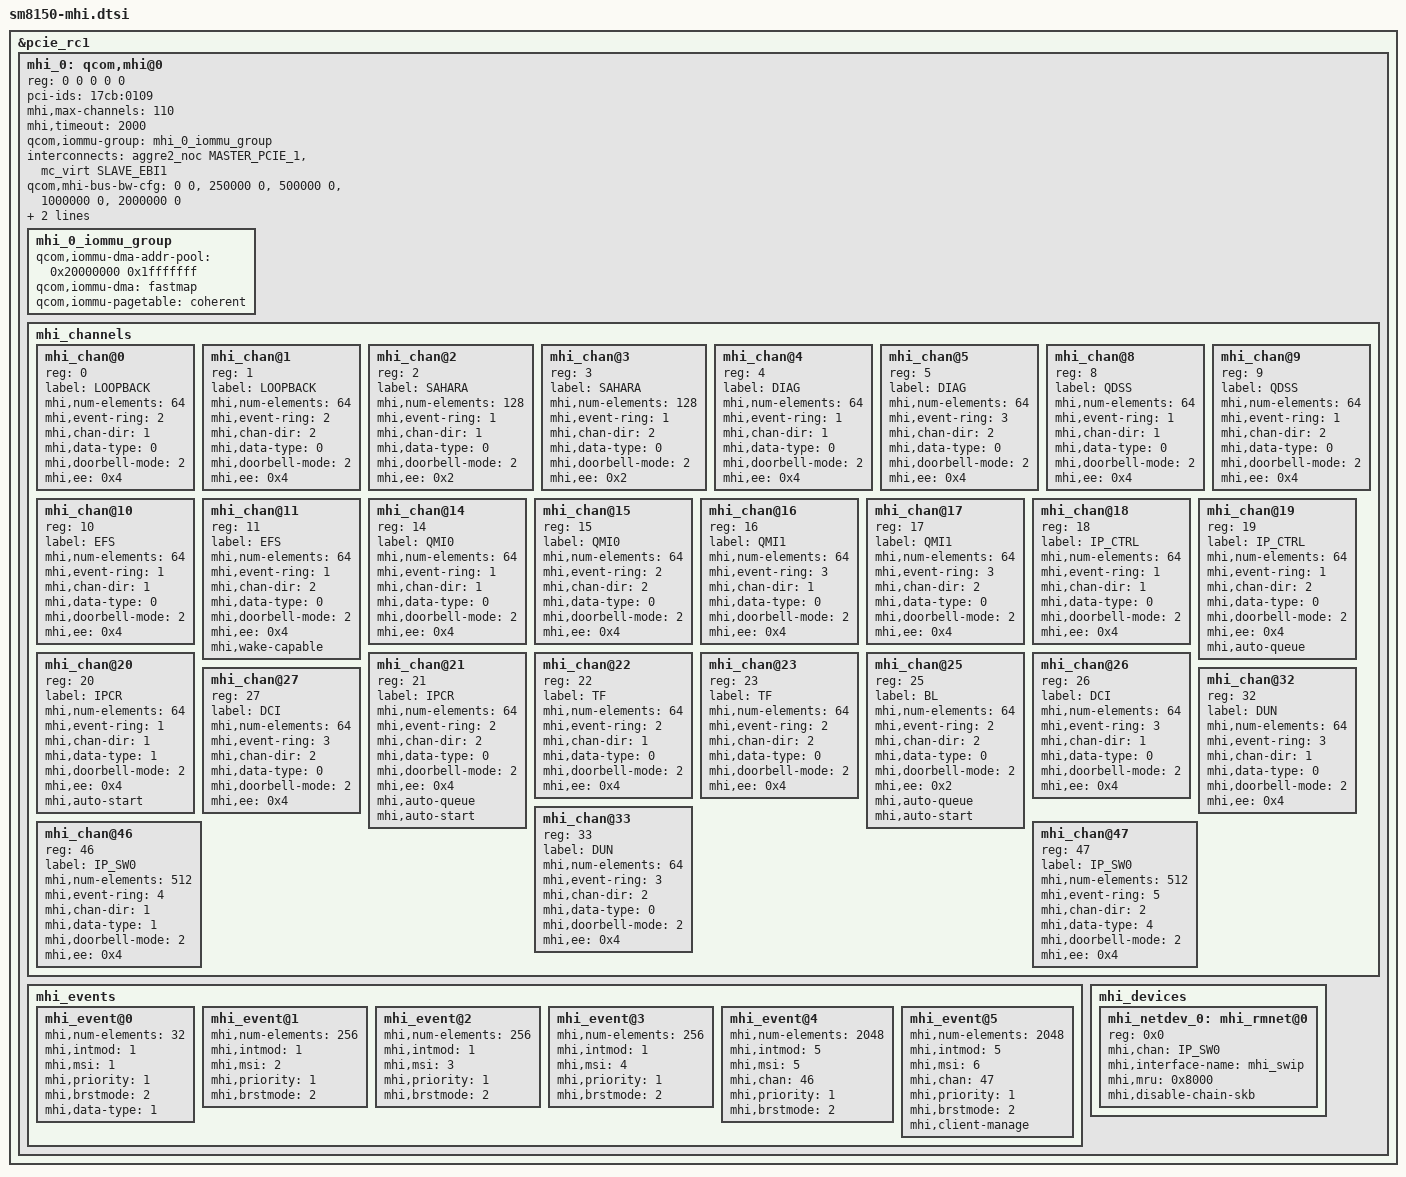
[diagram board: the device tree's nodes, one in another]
&pcie_rc1 {
	#address-cells = <5>;
	#size-cells = <0>;

	mhi_0: qcom,mhi@0 {
		reg = <0 0 0 0 0 >;

		pci-ids = "17cb:0109";

		/* mhi bus specific settings */
		mhi,max-channels = <110>;
		mhi,timeout = <2000>;
		qcom,iommu-group = <&mhi_0_iommu_group>;

		interconnect-names = "icc_path";
		interconnects = <&aggre2_noc MASTER_PCIE_1 &mc_virt SLAVE_EBI1>;
		qcom,mhi-bus-bw-cfg =
				<0 0>, /* no vote */
				<250000 0>, /* avg bw / AB: 2 GBps, peak bw / IB: no vote */
				<500000 0>, /* avg bw / AB: 4 GBps, peak bw / IB: no vote */
				<1000000 0>, /* avg bw / AB: 8 GBps, peak bw / IB: no vote */
				<2000000 0>; /* avg bw / AB: 16 GBps, peak bw / IB: no vote */
		mhi,skip-forced-suspend;
		mhi,allow-m1;

		#address-cells = <1>;
		#size-cells = <1>;

		mhi_0_iommu_group: mhi_0_iommu_group {
			qcom,iommu-dma-addr-pool = <0x20000000 0x1fffffff>;
			qcom,iommu-dma = "fastmap";
			qcom,iommu-pagetable = "coherent";
		};

		mhi_channels {
			#address-cells = <1>;
			#size-cells = <0>;
			mhi_chan@0 {
				reg = <0>;
				label = "LOOPBACK";
				mhi,num-elements = <64>;
				mhi,event-ring = <2>;
				mhi,chan-dir = <1>;
				mhi,data-type = <0>;
				mhi,doorbell-mode = <2>;
				mhi,ee = <0x4>;
			};

			mhi_chan@1 {
				reg = <1>;
				label = "LOOPBACK";
				mhi,num-elements = <64>;
				mhi,event-ring = <2>;
				mhi,chan-dir = <2>;
				mhi,data-type = <0>;
				mhi,doorbell-mode = <2>;
				mhi,ee = <0x4>;
			};

			mhi_chan@2 {
				reg = <2>;
				label = "SAHARA";
				mhi,num-elements = <128>;
				mhi,event-ring = <1>;
				mhi,chan-dir = <1>;
				mhi,data-type = <0>;
				mhi,doorbell-mode = <2>;
				mhi,ee = <0x2>;
			};

			mhi_chan@3 {
				reg = <3>;
				label = "SAHARA";
				mhi,num-elements = <128>;
				mhi,event-ring = <1>;
				mhi,chan-dir = <2>;
				mhi,data-type = <0>;
				mhi,doorbell-mode = <2>;
				mhi,ee = <0x2>;
			};

			mhi_chan@4 {
				reg = <4>;
				label = "DIAG";
				mhi,num-elements = <64>;
				mhi,event-ring = <1>;
				mhi,chan-dir = <1>;
				mhi,data-type = <0>;
				mhi,doorbell-mode = <2>;
				mhi,ee = <0x4>;
			};

			mhi_chan@5 {
				reg = <5>;
				label = "DIAG";
				mhi,num-elements = <64>;
				mhi,event-ring = <3>;
				mhi,chan-dir = <2>;
				mhi,data-type = <0>;
				mhi,doorbell-mode = <2>;
				mhi,ee = <0x4>;
			};

			mhi_chan@8 {
				reg = <8>;
				label = "QDSS";
				mhi,num-elements = <64>;
				mhi,event-ring = <1>;
				mhi,chan-dir = <1>;
				mhi,data-type = <0>;
				mhi,doorbell-mode = <2>;
				mhi,ee = <0x4>;
			};

			mhi_chan@9 {
				reg = <9>;
				label = "QDSS";
				mhi,num-elements = <64>;
				mhi,event-ring = <1>;
				mhi,chan-dir = <2>;
				mhi,data-type = <0>;
				mhi,doorbell-mode = <2>;
				mhi,ee = <0x4>;
			};

			mhi_chan@10 {
				reg = <10>;
				label = "EFS";
				mhi,num-elements = <64>;
				mhi,event-ring = <1>;
				mhi,chan-dir = <1>;
				mhi,data-type = <0>;
				mhi,doorbell-mode = <2>;
				mhi,ee = <0x4>;
			};

			mhi_chan@11 {
				reg = <11>;
				label = "EFS";
				mhi,num-elements = <64>;
				mhi,event-ring = <1>;
				mhi,chan-dir = <2>;
				mhi,data-type = <0>;
				mhi,doorbell-mode = <2>;
				mhi,ee = <0x4>;
				mhi,wake-capable;
			};

			mhi_chan@14 {
				reg = <14>;
				label = "QMI0";
				mhi,num-elements = <64>;
				mhi,event-ring = <1>;
				mhi,chan-dir = <1>;
				mhi,data-type = <0>;
				mhi,doorbell-mode = <2>;
				mhi,ee = <0x4>;
			};

			mhi_chan@15 {
				reg = <15>;
				label = "QMI0";
				mhi,num-elements = <64>;
				mhi,event-ring = <2>;
				mhi,chan-dir = <2>;
				mhi,data-type = <0>;
				mhi,doorbell-mode = <2>;
				mhi,ee = <0x4>;
			};

			mhi_chan@16 {
				reg = <16>;
				label = "QMI1";
				mhi,num-elements = <64>;
				mhi,event-ring = <3>;
				mhi,chan-dir = <1>;
				mhi,data-type = <0>;
				mhi,doorbell-mode = <2>;
				mhi,ee = <0x4>;
			};

			mhi_chan@17 {
				reg = <17>;
				label = "QMI1";
				mhi,num-elements = <64>;
				mhi,event-ring = <3>;
				mhi,chan-dir = <2>;
				mhi,data-type = <0>;
				mhi,doorbell-mode = <2>;
				mhi,ee = <0x4>;
			};

			mhi_chan@18 {
				reg = <18>;
				label = "IP_CTRL";
				mhi,num-elements = <64>;
				mhi,event-ring = <1>;
				mhi,chan-dir = <1>;
				mhi,data-type = <0>;
				mhi,doorbell-mode = <2>;
				mhi,ee = <0x4>;
			};

			mhi_chan@19 {
				reg = <19>;
				label = "IP_CTRL";
				mhi,num-elements = <64>;
				mhi,event-ring = <1>;
				mhi,chan-dir = <2>;
				mhi,data-type = <0>;
				mhi,doorbell-mode = <2>;
				mhi,ee = <0x4>;
				mhi,auto-queue;
			};

			mhi_chan@20 {
				reg = <20>;
				label = "IPCR";
				mhi,num-elements = <64>;
				mhi,event-ring = <1>;
				mhi,chan-dir = <1>;
				mhi,data-type = <1>;
				mhi,doorbell-mode = <2>;
				mhi,ee = <0x4>;
				mhi,auto-start;
			};

			mhi_chan@21 {
				reg = <21>;
				label = "IPCR";
				mhi,num-elements = <64>;
				mhi,event-ring = <2>;
				mhi,chan-dir = <2>;
				mhi,data-type = <0>;
				mhi,doorbell-mode = <2>;
				mhi,ee = <0x4>;
				mhi,auto-queue;
				mhi,auto-start;
			};

			mhi_chan@22 {
				reg = <22>;
				label = "TF";
				mhi,num-elements = <64>;
				mhi,event-ring = <2>;
				mhi,chan-dir = <1>;
				mhi,data-type = <0>;
				mhi,doorbell-mode = <2>;
				mhi,ee = <0x4>;
			};

			mhi_chan@23 {
				reg = <23>;
				label = "TF";
				mhi,num-elements = <64>;
				mhi,event-ring = <2>;
				mhi,chan-dir = <2>;
				mhi,data-type = <0>;
				mhi,doorbell-mode = <2>;
				mhi,ee = <0x4>;
			};

			mhi_chan@25 {
				reg = <25>;
				label = "BL";
				mhi,num-elements = <64>;
				mhi,event-ring = <2>;
				mhi,chan-dir = <2>;
				mhi,data-type = <0>;
				mhi,doorbell-mode = <2>;
				mhi,ee = <0x2>;
				mhi,auto-queue;
				mhi,auto-start;
			};

			mhi_chan@26 {
				reg = <26>;
				label = "DCI";
				mhi,num-elements = <64>;
				mhi,event-ring = <3>;
				mhi,chan-dir = <1>;
				mhi,data-type = <0>;
				mhi,doorbell-mode = <2>;
				mhi,ee = <0x4>;
			};

			mhi_chan@27 {
				reg = <27>;
				label = "DCI";
				mhi,num-elements = <64>;
				mhi,event-ring = <3>;
				mhi,chan-dir = <2>;
				mhi,data-type = <0>;
				mhi,doorbell-mode = <2>;
				mhi,ee = <0x4>;
			};

			mhi_chan@32 {
				reg = <32>;
				label = "DUN";
				mhi,num-elements = <64>;
				mhi,event-ring = <3>;
				mhi,chan-dir = <1>;
				mhi,data-type = <0>;
				mhi,doorbell-mode = <2>;
				mhi,ee = <0x4>;
			};

			mhi_chan@33 {
				reg = <33>;
				label = "DUN";
				mhi,num-elements = <64>;
				mhi,event-ring = <3>;
				mhi,chan-dir = <2>;
				mhi,data-type = <0>;
				mhi,doorbell-mode = <2>;
				mhi,ee = <0x4>;
			};

			mhi_chan@46 {
				reg = <46>;
				label = "IP_SW0";
				mhi,num-elements = <512>;
				mhi,event-ring = <4>;
				mhi,chan-dir = <1>;
				mhi,data-type = <1>;
				mhi,doorbell-mode = <2>;
				mhi,ee = <0x4>;
			};

			mhi_chan@47 {
				reg = <47>;
				label = "IP_SW0";
				mhi,num-elements = <512>;
				mhi,event-ring = <5>;
				mhi,chan-dir = <2>;
				mhi,data-type = <4>;
				mhi,doorbell-mode = <2>;
				mhi,ee = <0x4>;
			};
		};

		mhi_events {
			#address-cells = <1>;
			#size-cells = <0>;

			mhi_event@0 {
				mhi,num-elements = <32>;
				mhi,intmod = <1>;
				mhi,msi = <1>;
				mhi,priority = <1>;
				mhi,brstmode = <2>;
				mhi,data-type = <1>;
			};

			mhi_event@1 {
				mhi,num-elements = <256>;
				mhi,intmod = <1>;
				mhi,msi = <2>;
				mhi,priority = <1>;
				mhi,brstmode = <2>;
			};

			mhi_event@2 {
				mhi,num-elements = <256>;
				mhi,intmod = <1>;
				mhi,msi = <3>;
				mhi,priority = <1>;
				mhi,brstmode = <2>;
			};

			mhi_event@3 {
				mhi,num-elements = <256>;
				mhi,intmod = <1>;
				mhi,msi = <4>;
				mhi,priority = <1>;
				mhi,brstmode = <2>;
			};

			mhi_event@4 {
				mhi,num-elements = <2048>;
				mhi,intmod = <5>;
				mhi,msi = <5>;
				mhi,chan = <46>;
				mhi,priority = <1>;
				mhi,brstmode = <2>;
			};

			mhi_event@5 {
				mhi,num-elements = <2048>;
				mhi,intmod = <5>;
				mhi,msi = <6>;
				mhi,chan = <47>;
				mhi,priority = <1>;
				mhi,brstmode = <2>;
				mhi,client-manage;
			};
		};

		mhi_devices {
			#address-cells = <1>;
			#size-cells = <0>;
			mhi_netdev_0: mhi_rmnet@0 {
				reg = <0x0>;
				mhi,chan = "IP_SW0";
				mhi,interface-name = "mhi_swip";
				mhi,mru = <0x8000>;
				mhi,disable-chain-skb;
			};
		};
	};
};

